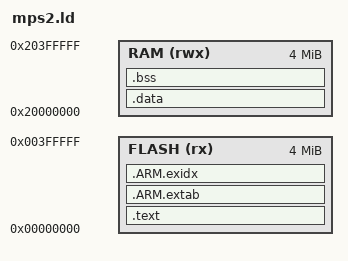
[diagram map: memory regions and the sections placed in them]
/* MPS2-AN385 (QEMU): 4 MiB SSRAM at 0x0 used as "flash", 4 MiB at 0x20000000 as RAM.
   QEMU loads every PT_LOAD segment at its LMA, so .data is placed directly in RAM
   (no copy loop needed by newlib's crt0). */
MEMORY {
  FLASH (rx)  : ORIGIN = 0x00000000, LENGTH = 4M
  RAM   (rwx) : ORIGIN = 0x20000000, LENGTH = 4M
}
ENTRY(Reset_Handler)
SECTIONS {
  .text : {
    KEEP(*(.vectors))
    *(.text*) *(.rodata*)
    KEEP(*(.init)) KEEP(*(.fini))
    . = ALIGN(4);
    __preinit_array_start = .; KEEP(*(.preinit_array)) __preinit_array_end = .;
    __init_array_start = .; KEEP(*(SORT(.init_array.*))) KEEP(*(.init_array)) __init_array_end = .;
    __fini_array_start = .; KEEP(*(SORT(.fini_array.*))) KEEP(*(.fini_array)) __fini_array_end = .;
  } > FLASH
  .ARM.extab : { *(.ARM.extab* .gnu.linkonce.armextab.*) } > FLASH
  .ARM.exidx : { __exidx_start = .; *(.ARM.exidx* .gnu.linkonce.armexidx.*) __exidx_end = .; } > FLASH
  .data : { *(.data*) . = ALIGN(4); } > RAM
  .bss (NOLOAD) : { __bss_start__ = .; *(.bss*) *(COMMON) . = ALIGN(8); __bss_end__ = .; } > RAM
  end = .; __end__ = .; PROVIDE(_end = .);
  __stack = ORIGIN(RAM) + LENGTH(RAM);
  __HeapLimit = __stack - 0x10000;
}
